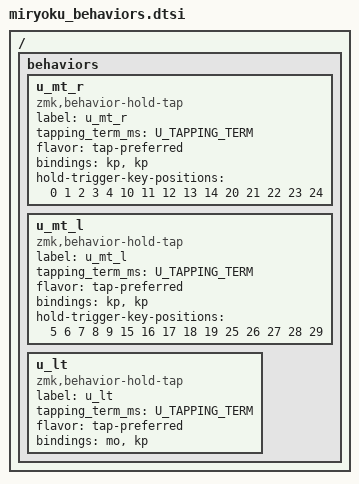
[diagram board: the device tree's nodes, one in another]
// Copyright 2022 Manna Harbour
// https://github.com/manna-harbour/miryoku

/ {
  behaviors {
    u_mt_r: u_mt_r {
      compatible = "zmk,behavior-hold-tap";
      label = "u_mt_r";
      #binding-cells = <2>;
      tapping_term_ms = <U_TAPPING_TERM>;
      flavor = "tap-preferred";
      bindings = <&kp>, <&kp>;
      hold-trigger-key-positions = <0 1 2 3 4 10 11 12 13 14 20 21 22 23 24>;
    };
    u_mt_l: u_mt_l {
      compatible = "zmk,behavior-hold-tap";
      label = "u_mt_l";
      #binding-cells = <2>;
      tapping_term_ms = <U_TAPPING_TERM>;
      flavor = "tap-preferred";
      bindings = <&kp>, <&kp>;
      hold-trigger-key-positions = <5 6 7 8 9 15 16 17 18 19 25 26 27 28 29>;
    };
    u_lt: u_lt {
      compatible = "zmk,behavior-hold-tap";
      label = "u_lt";
      #binding-cells = <2>;
      tapping_term_ms = <U_TAPPING_TERM>;
      flavor = "tap-preferred";
      bindings = <&mo>, <&kp>;
    };
  };
};
